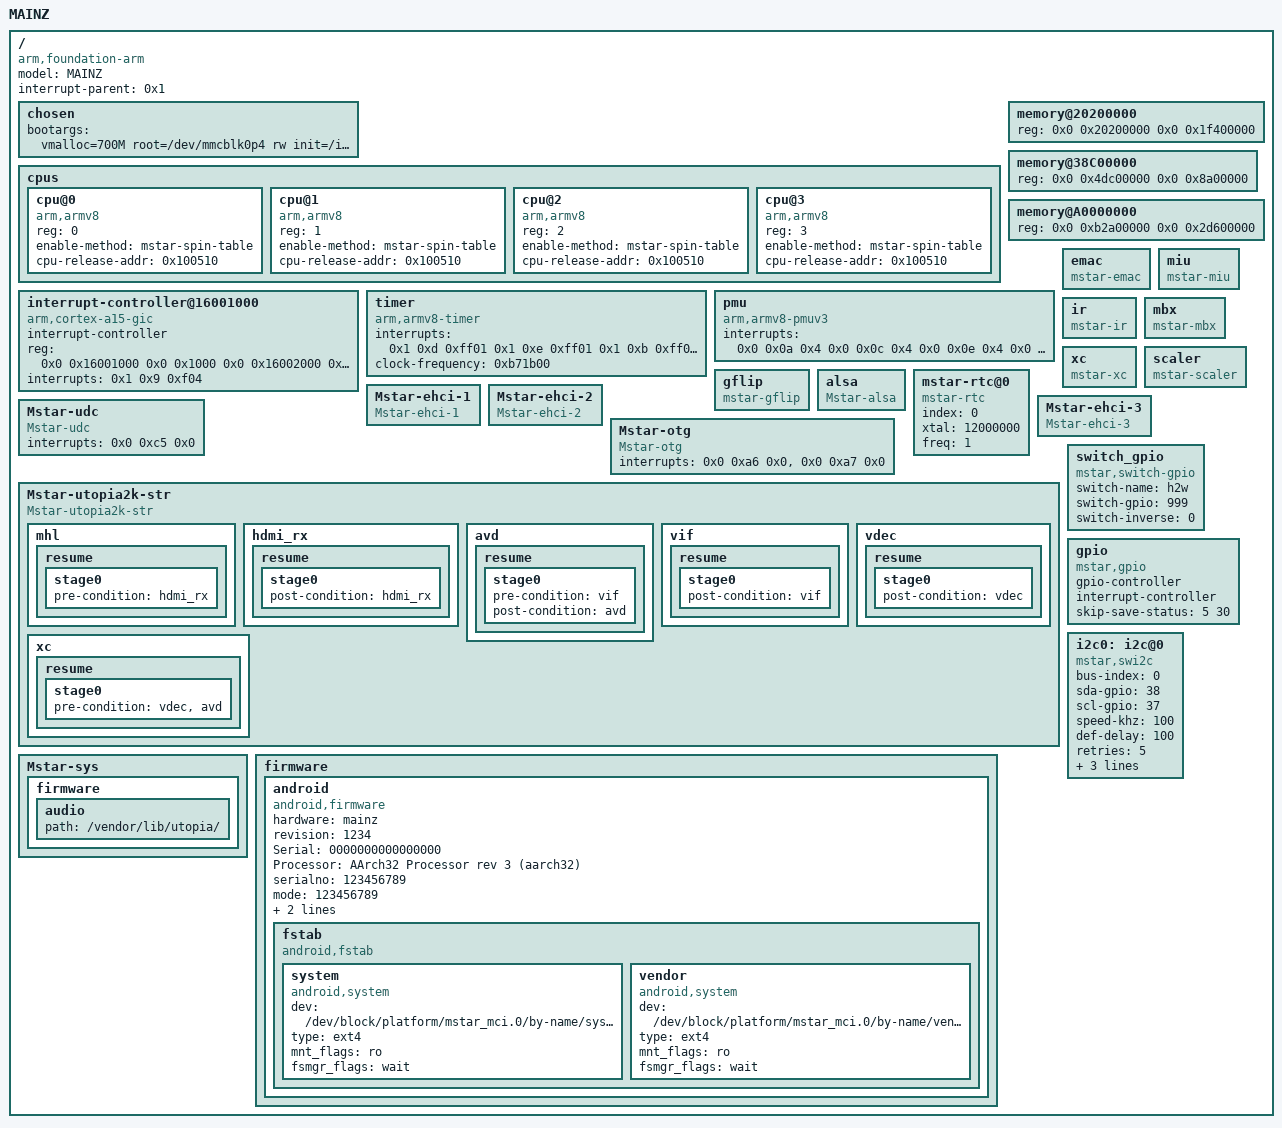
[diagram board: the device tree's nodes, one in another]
/dts-v1/;
/ {
	model = "MAINZ";
	compatible = "arm,foundation-arm", "arm,mainz";
	interrupt-parent = <0x1>;
	#address-cells = <0x2>;
	#size-cells = <0x2>;

	chosen {
		bootargs = "vmalloc=700M root=/dev/mmcblk0p4 rw init=/init ip=dhcp console=ttyS0,115200 delaylogo=true CLOSE_BOOTLOGO bootlogo_dfblayer=2 panel_path=/ BRICK_TERMINATOR_SPI_STATUS_OF FSET=00173E00 EMAC_MEM=0x100000 PM51_ADDR=0x20010000 PM51_LEN=0x10000 SAR5=ON MIRROR=0 BOOTLOGO_IN_MBOOT ENV_VAR_OFFSET=0x0 ENV_VAR_SIZE=0x10000 ENV=EMMC SECURITY=OFF LX_MEM=0x3200000 LX_MEM2=0x2BF00000,0x9200000 LX_MEM3=0xAD400000,0x2A00000";
	};

	cpus {
		#address-cells = <0x1>;
		#size-cells = <0x0>;

		cpu@0 {
			device_type = "cpu";
			compatible = "arm,armv8";
			reg = <0>;
			enable-method = "mstar-spin-table";
			cpu-release-addr = <0x100510>;
		};

		cpu@1 {
			device_type = "cpu";
			compatible = "arm,armv8";
			reg = <1>;
			enable-method = "mstar-spin-table";
			cpu-release-addr = <0x100510>;
		};

		cpu@2 {
			device_type = "cpu";
			compatible = "arm,armv8";
			reg = <2>;
			enable-method = "mstar-spin-table";
			cpu-release-addr = <0x100510>;
		};

		cpu@3 {
			device_type = "cpu";
			compatible = "arm,armv8";
			reg = <3>;
			enable-method = "mstar-spin-table";
			cpu-release-addr = <0x100510>;
		};

	};

	memory@20200000 {
		device_type = "memory";
		reg = <0x0 0x20200000 0x0 0x1f400000>;
	};

	memory@38C00000 {
		device_type = "memory";
		reg = <0x0 0x4dc00000 0x0 0x8a00000>;
	};

        memory@A0000000 {
                device_type = "memory";
                reg = <0x0 0xb2a00000 0x0 0x2d600000>;
        };


	interrupt-controller@16001000 {
		compatible = "arm,cortex-a15-gic", "arm,cortex-a9-gic";
		#interrupt-cells = <0x3>;
		#address-cells = <0x0>;
		interrupt-controller;
		reg = <0x0 0x16001000 0x0 0x1000 0x0 0x16002000 0x0 0x4000>;
		interrupts = <0x1 0x9 0xf04>;
		linux,phandle = <0x1>;
		phandle = <0x1>;
	};

	timer {
		compatible = "arm,armv8-timer";
		interrupts = <0x1 0xd 0xff01 0x1 0xe 0xff01 0x1 0xb 0xff01 0x1 0xa 0xff01>;
		clock-frequency = <0xb71b00>;
	};

	pmu {
		compatible = "arm,armv8-pmuv3";
		interrupts = <0x0 0x0a 0x4 0x0 0x0c 0x4 0x0 0x0e 0x4 0x0 0x10 0x4>;
	};

	emac {
		compatible = "mstar-emac";
	};

    miu {
        compatible = "mstar-miu";
    };

        ir {
	        compatible = "mstar-ir";
	};

	mbx {
	        compatible = "mstar-mbx";
	};

	xc {
		compatible = "mstar-xc";
	};

	scaler {
		compatible = "mstar-scaler";
	};

	gflip {
		compatible = "mstar-gflip";
	};

	alsa {
		compatible = "Mstar-alsa";
	};

	mstar-rtc@0 {
		compatible = "mstar-rtc";
		index = <0>;
		xtal = <12000000>;
		freq = <1>;
	};

	Mstar-ehci-1 {
		compatible = "Mstar-ehci-1";
	};

	Mstar-ehci-2 {
		compatible = "Mstar-ehci-2";
	};

	Mstar-ehci-3 {
		compatible = "Mstar-ehci-3";
	};

  Mstar-udc {
	compatible = "Mstar-udc";
	interrupts = <0x0 0xc5 0x0>;
	};

  Mstar-otg {
	compatible = "Mstar-otg";
	interrupts = <0x0 0xa6 0x0>, <0x0 0xa7 0x0>;
	};

	Mstar-utopia2k-str {
		compatible = "Mstar-utopia2k-str";
		mhl {
		  resume {
		    stage0 {
		      pre-condition = "hdmi_rx";
		    };
		  };
		};
		hdmi_rx {
		  resume {
		    stage0 {
		      post-condition = "hdmi_rx";
		    };
		  };
		};
		avd {
		  resume {
		    stage0 {
		      pre-condition = "vif";
		      post-condition = "avd";
		    };
		  };
		};
		vif {
		  resume {
		    stage0 {
		      post-condition = "vif";
		    };
		  };
		};
		vdec {
		  resume {
		    stage0 {
		      post-condition = "vdec";
		    };
		  };
		};
		xc {
		  resume {
		    stage0 {
		      pre-condition = "vdec","avd";
		    };
		  };
		};
	};

	Mstar-sys {
		firmware {
			audio {
				path = "/vendor/lib/utopia/";
			};
		};
	};

	firmware {
		android {
			compatible = "android,firmware";
			hardware ="mainz";
			revision ="1234";
			Serial   ="0000000000000000";
			Processor ="AArch32 Processor rev 3 (aarch32)";
			serialno ="123456789";
			mode ="123456789";
			baseband ="123456789";
			bootloader ="123456789";
			fstab {
				compatible = "android,fstab";
				system {
					compatible = "android,system";
					dev = "/dev/block/platform/mstar_mci.0/by-name/system";
					type = "ext4";
					mnt_flags = "ro";
					fsmgr_flags = "wait";
				};
				vendor {
					compatible = "android,system";
					dev = "/dev/block/platform/mstar_mci.0/by-name/vendor";
					type = "ext4";
					mnt_flags = "ro";
					fsmgr_flags = "wait";
				};
			};
		};
	};

	switch_gpio {
		compatible = "mstar,switch-gpio";
		switch-name = "h2w";
		switch-gpio = <999>;
		switch-inverse = <0>;
	};

	gpio: gpio{
		compatible = "mstar,gpio";
		gpio-controller;
		#gpio-cells = <1>;
		interrupt-controller;
		skip-save-status = <5 30>;
		#interrupt-cells = <2>; /* cell name GPIO_PAD, trigger-type*/
	};

	i2c0: i2c@0 {
		compatible = "mstar,swi2c";
		bus-index = <0>;
		sda-gpio = <38>;
		scl-gpio = <37>;
		speed-khz = <100>;
		def-delay = <100>;
		retries = <5>;
		status = "okay";
		iic-mode = <1>;
		hw-port = <0>;
		pad-mux = <1>;
	};
};
